# Polarfire SoC register map
Vendor: Microchip; File version: 1.0
CPU: Microchip PolarFire SoC 1.0, little endian
Registers are 32-bit, read-write, reset 0x0 unless marked. A register's access mark holds for its fields unless they carry their own. Offsets are from the block's base; [hi:lo] are bit positions; lines under a group give offsets from that group; {n}, {i} and the like mark numbered series; 'fields as' and 'values as' point back to an identical list.

## MPUCFG — MPUCFG Controller
Base 0x20005000
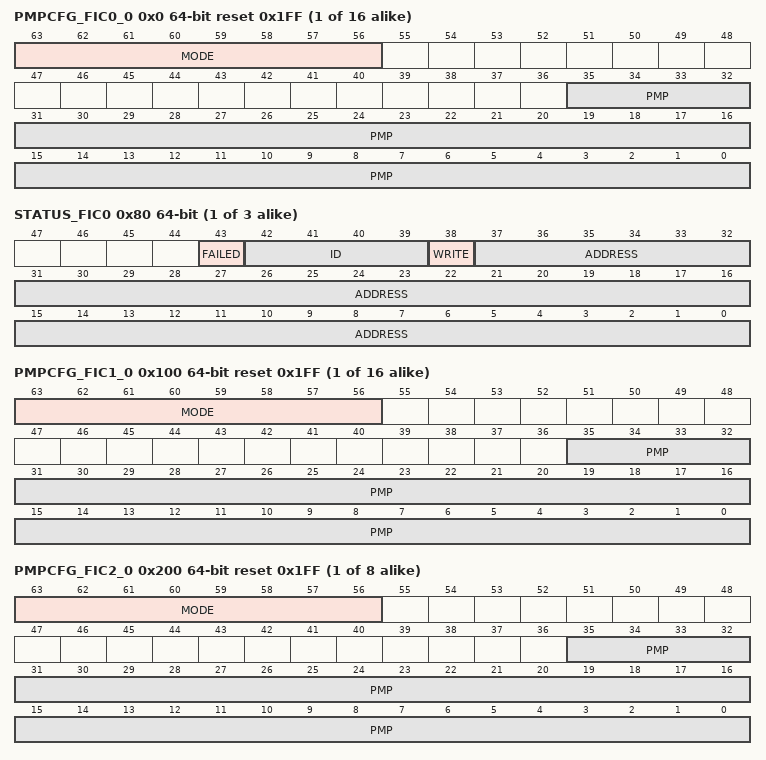
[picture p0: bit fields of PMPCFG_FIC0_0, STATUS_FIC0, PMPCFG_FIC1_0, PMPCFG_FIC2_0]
{0x0+8i} PMPCFG_FIC0_{i} 64-bit reset 0x1FF (i=0..15)
  [63:56] MODE — Bit 63: LOCKED When set to 1 the configuration cannot be changed until a reset occurs. Bits 62 : 61 reserved Bits 60:59: Match 00=OFF 01=TOR 10=NA4 11=NAPOT Only 00 and 11 are supported, TOR and NAT settings are equivalent to off Bit 58: Execute enable Bit 57: Write Enable Bit 56: Read Enable
  [35:0] PMP — The PMP Value, bits 8:0 are hardwired to 9'h1ff forcing a minimum block size of 4K bytes
{0x80+0x100*i} STATUS_FIC{i} 64-bit ro (i=0..2)
  [43] FAILED rw — Indicates Failure occurred, cleared via a system register bit
  [42:39] ID rw — AXI ID of failure (4-bits)
  [38] WRITE rw — 0=Read 1=Write
  [37:0] ADDRESS rw — 38-bit failed address
{0x100+8i} PMPCFG_FIC1_{i} 64-bit reset 0x1FF (i=0..15)
  fields as PMPCFG_FIC0_0
{0x200+8i} PMPCFG_FIC2_{i} 64-bit reset 0x1FF (i=0..7)
  fields as PMPCFG_FIC0_0
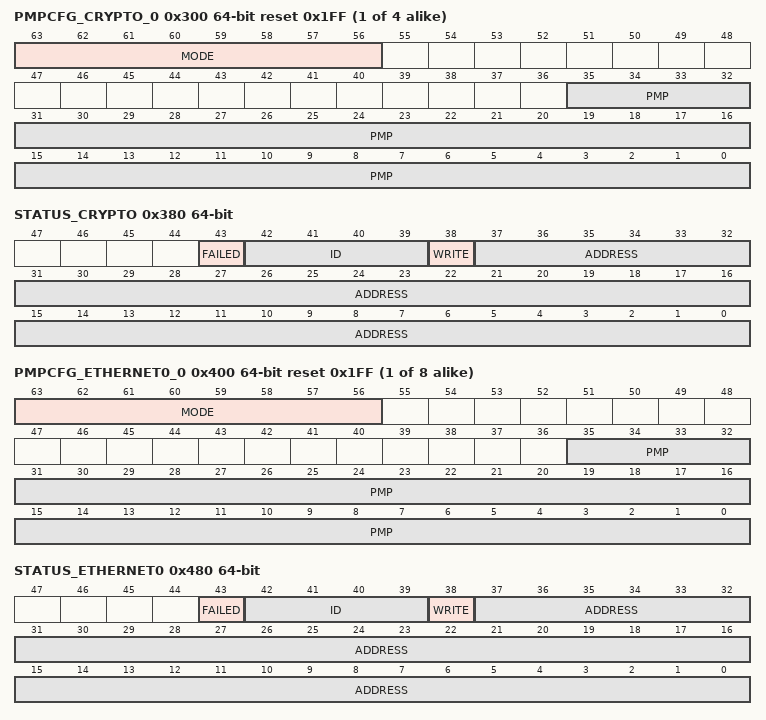
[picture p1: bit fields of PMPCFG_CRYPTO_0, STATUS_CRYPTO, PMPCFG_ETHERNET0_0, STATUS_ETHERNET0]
{0x300+8i} PMPCFG_CRYPTO_{i} 64-bit reset 0x1FF (i=0..3)
  fields as PMPCFG_FIC0_0
0x380 STATUS_CRYPTO 64-bit ro
  fields as STATUS_FIC0
{0x400+8i} PMPCFG_ETHERNET0_{i} 64-bit reset 0x1FF (i=0..7)
  fields as PMPCFG_FIC0_0
0x480 STATUS_ETHERNET0 64-bit ro
  fields as STATUS_FIC0
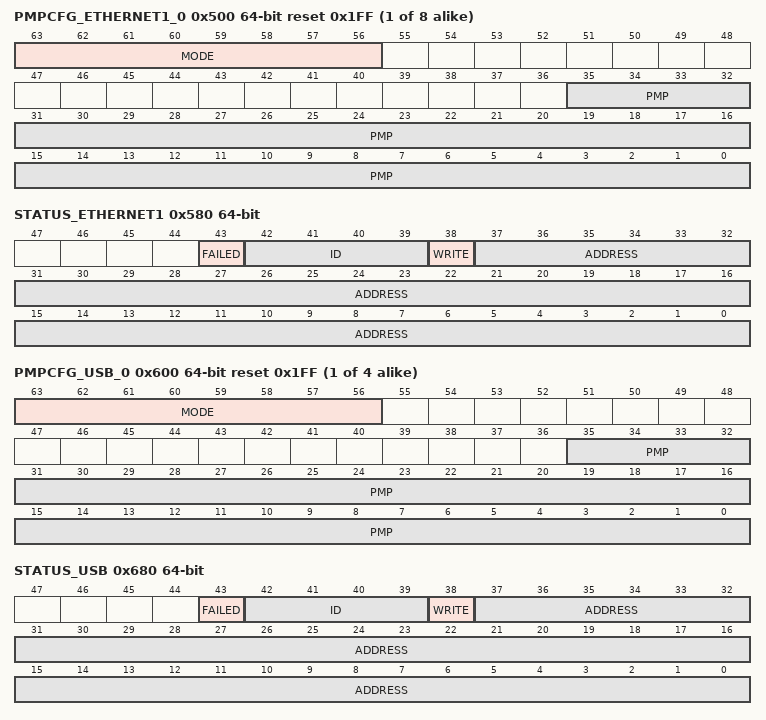
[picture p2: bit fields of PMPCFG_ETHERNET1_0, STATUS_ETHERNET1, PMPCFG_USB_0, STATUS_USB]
{0x500+8i} PMPCFG_ETHERNET1_{i} 64-bit reset 0x1FF (i=0..7)
  fields as PMPCFG_FIC0_0
0x580 STATUS_ETHERNET1 64-bit ro
  fields as STATUS_FIC0
{0x600+8i} PMPCFG_USB_{i} 64-bit reset 0x1FF (i=0..3)
  fields as PMPCFG_FIC0_0
0x680 STATUS_USB 64-bit ro
  fields as STATUS_FIC0
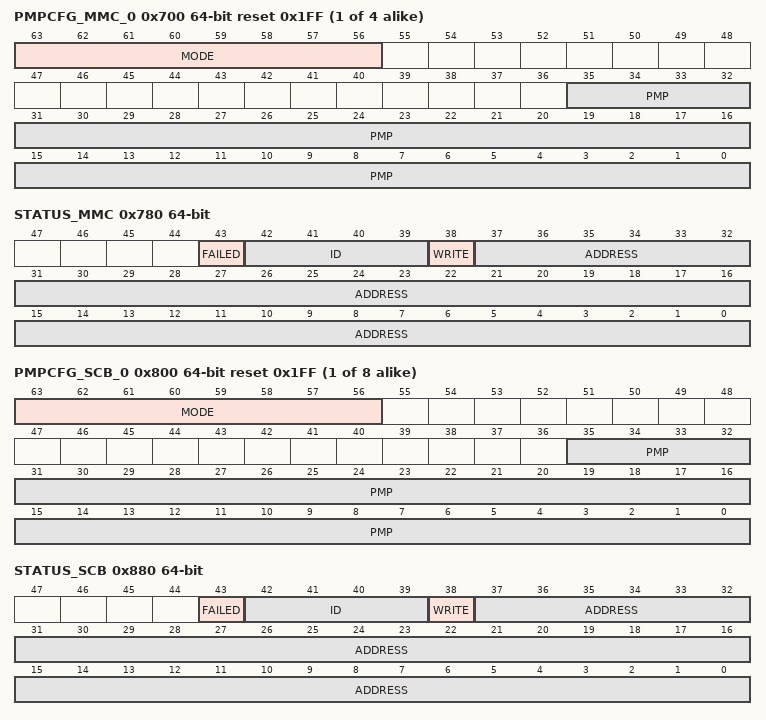
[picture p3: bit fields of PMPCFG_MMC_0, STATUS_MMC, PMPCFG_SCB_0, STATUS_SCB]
{0x700+8i} PMPCFG_MMC_{i} 64-bit reset 0x1FF (i=0..3)
  fields as PMPCFG_FIC0_0
0x780 STATUS_MMC 64-bit ro
  fields as STATUS_FIC0
{0x800+8i} PMPCFG_SCB_{i} 64-bit reset 0x1FF (i=0..7)
  fields as PMPCFG_FIC0_0
0x880 STATUS_SCB 64-bit ro
  fields as STATUS_FIC0
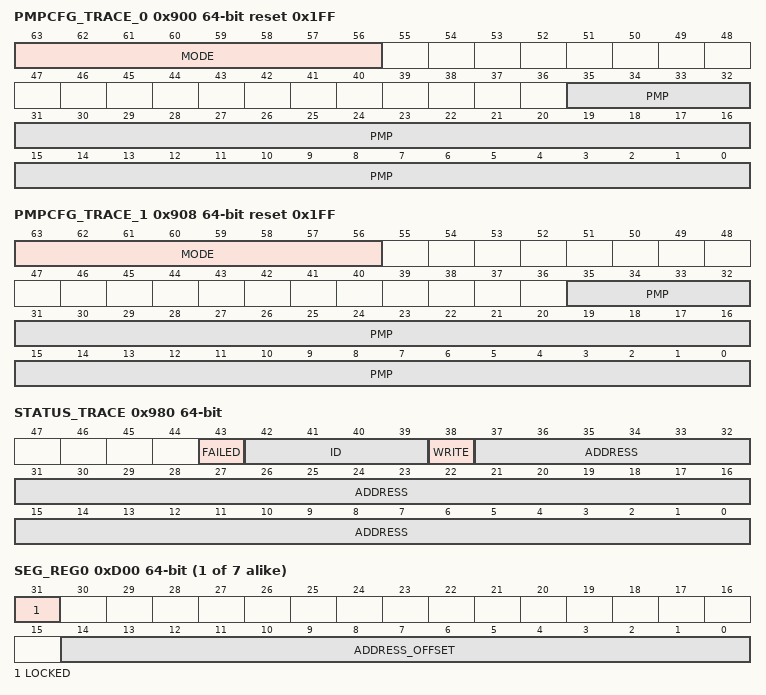
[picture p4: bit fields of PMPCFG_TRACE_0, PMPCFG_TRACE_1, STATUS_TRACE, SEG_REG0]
0x900 PMPCFG_TRACE_0 64-bit reset 0x1FF
  fields as PMPCFG_FIC0_0
0x908 PMPCFG_TRACE_1 64-bit reset 0x1FF
  fields as PMPCFG_FIC0_0
0x980 STATUS_TRACE 64-bit ro
  fields as STATUS_FIC0
{0xD00+8i} SEG_REG{i} 64-bit (i=0..6) — Cached access at 0x00_8000_0000
  [31] LOCKED — When set to '1' the configuration cannot be changed until a reset occurs.
  [14:0] ADDRESS_OFFSET — This sets offset that is added to address bits [37:24] to convert the Corecomplex address to DDR address. Value is twos complement allowing the value to be decremented.

## FRQMETER — FRQMETER Controller
Base 0x20006000
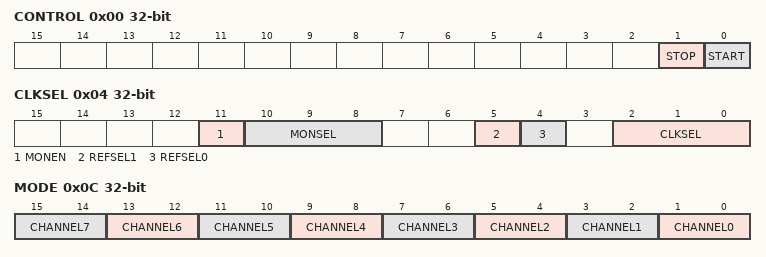
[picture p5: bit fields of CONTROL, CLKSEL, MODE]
0x00 CONTROL
  [1] STOP — Writing a '1' will cause the current measurement to be stopped. This bit is used to terminate a time measurement activity, or abort a frequency measurement The abort process may take several clock cycles and when complete the BUSY bit will return to '0'
  [0] START — Writing a '1' to this bit causes the measurement circuitry to start This bit will go back to a '0' when the measurement is complete
0x04 CLKSEL — clock select register
  [11] MONEN — Enables the clock monitor output
  [10:8] MONSEL — Selects which channel drives the clock monitor output 0 to 7.
  [5] REFSEL1 — When in timer mode allows the ATPG (Corners) / clkref3 (controller) clock input to clock the channel counters. This clock input is expected to be sourced from an on-chip PLL to support at-speed testing. This allows the timer to clocked off a much higher clock frequency than the reference counter that is limited to 100MHz.
  [4] REFSEL0 — Selects the reference input 0: clkref1 1: clkref2
  [2:0] CLKSEL — Selects which group of clock inputs are selected by the channels, controls the input multiplexer
0x08 RUNTIME reset 0x2710
  [23:0] REFCOUNT — Sets the reference count. When set to 0x000000 the timer will run forever i.e. until stopped by the CPU. This setting should not be used for frequency measurement.
0x0C MODE — Sets the measurement mode of channel: 2'b00: Disabled 2'b01: Frequency Mode 2'b11: Time Mode 2'b10: Reserved When N is less than 8 unimplemented channels will return disabled and cannot be enabled
  [2n+1:2n] CHANNEL{n} (n=0..7)
{0x10+4i} COUNT{i} ro (i=0..7)
  [23:0] COUNT — Returns the count value
